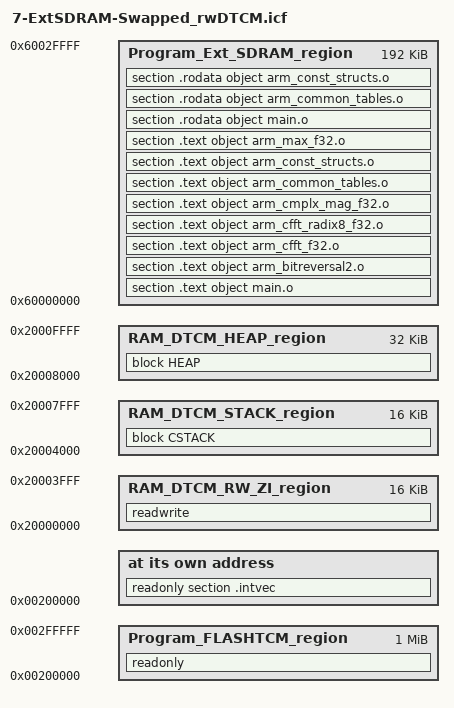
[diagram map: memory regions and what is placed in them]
/*###ICF### Section handled by ICF editor, don't touch! ****/
/*-Editor annotation file-*/
/* IcfEditorFile="$TOOLKIT_DIR$\config\ide\IcfEditor\cortex_v1_0.xml" */
/*-Specials-*/
define symbol __ICFEDIT_intvec_start__ = 0x00200000;

/*= Code region(s) ===================================== */
/* -- Program region in internal Flash ----------------- */
define symbol __ICFEDIT_Program_In_FLASHTCM_start__    = 0x00200000;
define symbol __ICFEDIT_Program_In_FLASHTCM_end__      = 0x002FFFFF;
/* -- Program region in SDRAM ------------------------- */
define symbol __ICFEDIT_Program_In_Ext_SDRAM_start__    = 0x60000000;
define symbol __ICFEDIT_Program_In_Ext_SDRAM_end__      = 0x6002FFFF;

/*= Data region(s) ===================================== */
/* RAM -- +RW +ZI region ------------------------------- */
/* The RW and Zero Initialized data will be in RAM-DTCM (0x4000 = 16k)
  All global variables will be located in this section. */
define symbol __ICFEDIT_region_RW_ZI_RAM_DTCM_start__  = 0x20000000;
define symbol __ICFEDIT_region_RW_ZI_RAM_DTCM_end__    = 0x20003FFF;

/* RAM -- STACK region --------------------------------- */
/* The Stack of the main application will be in RAM-DTCM (0x4000 = 16k)
 All internal variables of called functions will be located in this region. */
define symbol __ICFEDIT_region_STACK_RAM_DTCM_start__  = 0x20004000;
define symbol __ICFEDIT_region_STACK_RAM_DTCM_end__    = 0x20007FFF;

/* RAM -- HEAP region ---------------------------------- */
/* The Heap of the main application will be in RAM-DTCM (0x8000 = 32k)
 All dynamic allocations data got by malloc, realloc, calloc... will be located
 in this region.*/
define symbol __ICFEDIT_region_HEAP_RAM_DTCM_start__   = 0x20008000;
define symbol __ICFEDIT_region_HEAP_RAM_DTCM_end__     = 0x2000FFFF;

/*= STACK and Heap Sizes =============================== */
define symbol __ICFEDIT_size_cstack__ = 0x4000;  /* 16k */
define symbol __ICFEDIT_size_heap__   = 0x8000;  /* 32k */
/**** End of ICF editor section. ###ICF###*/

/*= Memory regions definition ========================== */
define memory mem with size = 4G;
define region Program_FLASHTCM_region = mem:[from __ICFEDIT_Program_In_FLASHTCM_start__ to __ICFEDIT_Program_In_FLASHTCM_end__];
define region Program_Ext_SDRAM_region = mem:[from __ICFEDIT_Program_In_Ext_SDRAM_start__ to __ICFEDIT_Program_In_Ext_SDRAM_end__];
define region RAM_DTCM_RW_ZI_region    = mem:[from __ICFEDIT_region_RW_ZI_RAM_DTCM_start__ to __ICFEDIT_region_RW_ZI_RAM_DTCM_end__];
define region RAM_DTCM_STACK_region    = mem:[from __ICFEDIT_region_STACK_RAM_DTCM_start__ to __ICFEDIT_region_STACK_RAM_DTCM_end__];
define region RAM_DTCM_HEAP_region     = mem:[from __ICFEDIT_region_HEAP_RAM_DTCM_start__ to __ICFEDIT_region_HEAP_RAM_DTCM_end__];


define block CSTACK    with alignment = 8, size = __ICFEDIT_size_cstack__   { };
define block HEAP      with alignment = 8, size = __ICFEDIT_size_heap__     { };

initialize by copy { readwrite,
                    /* Copy also the constants of these objects in RAM-ITCM */
                     ro object  arm_bitreversal2.o,
                     ro object  arm_cfft_f32.o,
                     ro object  arm_cfft_radix8_f32.o,
                     ro object  arm_cmplx_mag_f32.o,
                     ro object  arm_common_tables.o,
                     ro object  arm_const_structs.o,
                     ro object  arm_max_f32.o,
					 ro object  main.o
                   };                 
     
do not initialize  { section .noinit };

place at address mem:__ICFEDIT_intvec_start__ { readonly section .intvec };

place in Program_FLASHTCM_region { readonly };


place in Program_Ext_SDRAM_region  { 
                                    section .text object main.o,
                                    section .text object arm_bitreversal2.o,
                                    section .text object arm_cfft_f32.o,
                                    section .text object arm_cfft_radix8_f32.o,
                                    section .text object arm_cmplx_mag_f32.o,
                                    section .text object arm_common_tables.o,
                                    section .text object arm_const_structs.o,
                                    section .text object arm_max_f32.o,
									/*  Place also const data in FMC-SDRAM. Note that the files arm_bitreversal2_keil.c,  
	                                    arm_cfft_f32.c, arm_cfft_radix8_f32.c, arm_cmplx_mag_f32.c and arm_max_f32.c don't 
                                        contain huge const data. */
				                    section .rodata object  main.o,
                                    section .rodata object  arm_common_tables.o,
                                    section .rodata object  arm_const_structs.o 
		                          };

place in RAM_DTCM_RW_ZI_region  { readwrite };
place in RAM_DTCM_STACK_region  { block CSTACK };
place in RAM_DTCM_HEAP_region   { block HEAP };	

/*  RAM-DTCM partitioning:
 RAM-DTCM partitioning:
             ____________________    __ 0x20000000  RW/ZI region TOP
            |               |    |
            |               |    |
            |    RW & ZI   \ /   |   -> 16k
            |               v    |
            |____________________|   __ 0x20004000
            |                    |
            |                    |
            |               ^    |   -> 16k
            |      Stack   / \   |
            |               |    |
            |_______________|____|   __ 0x20008000 STACK region TOP / Heap region TOP 
            |   |                | 
            |   |                | 
            |  \ /   Heap        |  -> 32k
            |   v                | 
            |____________________|   __ 0x20010000


 Default SDRAM partitioning:
             ____________________    __ 0x60000000  
            |                    |
            |        192k       |
            |    for program     |    
            |                    |
            |____________________|   __ 0x60030000
            |                    |
            |  LCD frame buffer  |
*/	 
